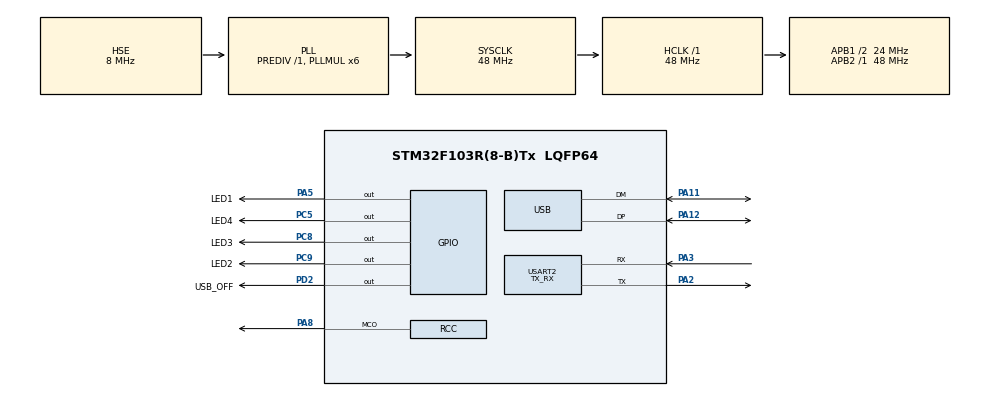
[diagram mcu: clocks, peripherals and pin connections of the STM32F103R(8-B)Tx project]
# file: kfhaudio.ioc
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Mcu.Family=STM32F1
Mcu.Name=STM32F103R(8-B)Tx
Mcu.Package=LQFP64
NVIC.PriorityGroup=NVIC_PRIORITYGROUP_4
NVIC.USB_LP_CAN1_RX0_IRQn=true\:0\:0\:false\:false\:true\:false\:true
PA11.Mode=Device
PA11.Signal=USB_DM
PA12.Mode=Device
PA12.Signal=USB_DP
PA13.Mode=Serial_Wire
PA13.Signal=SYS_JTMS-SWDIO
PA14.Mode=Serial_Wire
PA14.Signal=SYS_JTCK-SWCLK
PA2.Mode=Asynchronous
PA2.Signal=USART2_TX
PA3.Mode=Asynchronous
PA3.Signal=USART2_RX
PA5.GPIO_Label=LED1
PA5.Signal=GPIO_Output
PA8.GPIO_Speed=GPIO_SPEED_FREQ_HIGH
PA8.Mode=Clock-out
PA8.Signal=RCC_MCO
PC5.GPIO_Label=LED4
PC5.Signal=GPIO_Output
PC8.GPIO_Label=LED3
PC8.Signal=GPIO_Output
PC9.GPIO_Label=LED2
PC9.Signal=GPIO_Output
PD0-OSC_IN.Mode=HSE-External-Oscillator
PD0-OSC_IN.Signal=RCC_OSC_IN
PD1-OSC_OUT.Mode=HSE-External-Oscillator
PD1-OSC_OUT.Signal=RCC_OSC_OUT
PD2.GPIO_Label=USB_OFF
PD2.GPIO_PuPd=GPIO_PULLDOWN
PD2.Signal=GPIO_Output
ProjectManager.HeapSize=0x200
ProjectManager.StackSize=0x400
ProjectManager.TargetToolchain=SW4STM32
RCC.AHBFreq_Value=48000000
RCC.APB1CLKDivider=RCC_HCLK_DIV2
RCC.APB1Freq_Value=24000000
RCC.APB1TimFreq_Value=48000000
RCC.APB2Freq_Value=48000000
RCC.APB2TimFreq_Value=48000000
RCC.HCLKFreq_Value=48000000
RCC.PLLMUL=RCC_PLL_MUL6
RCC.RCC_MCOSource=RCC_MCO1SOURCE_PLLCLK
RCC.SYSCLKFreq_VALUE=48000000
RCC.SYSCLKSource=RCC_SYSCLKSOURCE_PLLCLK
RCC.USBFreq_Value=48000000
USART2.Mode=MODE_TX_RX
USART2.VirtualMode=VM_ASYNC
USB_DEVICE.CLASS_NAME_FS=CDC
USB_DEVICE.MANUFACTURER_STRING=SQ8KFH
USB_DEVICE.PRODUCT_STRING_CDC_FS=KFH Audio
USB_DEVICE.VirtualMode=Cdc
USB_DEVICE.VirtualModeFS=Cdc_FS
VP_USB_DEVICE_VS_USB_DEVICE_CDC_FS.Mode=CDC_FS
board=custom

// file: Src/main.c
/* USER CODE BEGIN Header */
/**
  ******************************************************************************
  * @file           : main.c
  * @brief          : Main program body
  ******************************************************************************
  * @attention
  *
  * <h2><center>&copy; Copyright (c) 2020 STMicroelectronics.
  * All rights reserved.</center></h2>
  *
  * This software component is licensed by ST under Ultimate Liberty license
  * SLA0044, the "License"; You may not use this file except in compliance with
  * the License. You may obtain a copy of the License at:
  *                             www.st.com/SLA0044
  *
  ******************************************************************************
  */
/* USER CODE END Header */
#include "main.h"
#include "usb_device.h"

UART_HandleTypeDef huart2;

void SystemClock_Config(void);
static void MX_GPIO_Init(void);
static void MX_USART2_UART_Init(void);

/* USER CODE BEGIN 0 */

int __io_putchar(int ch) {
	HAL_UART_Transmit(&huart2, (uint8_t*)&ch, 1, 1000);
	return ch;
}

/* USER CODE END 0 */

int main(void)
{

  /* MCU Configuration--------------------------------------------------------*/

  /* Reset of all peripherals, Initializes the Flash interface and the Systick. */
  HAL_Init();

  /* Configure the system clock */
  SystemClock_Config();

  /* Initialize all configured peripherals */
  MX_GPIO_Init();
  MX_USART2_UART_Init();
  MX_USB_DEVICE_Init();

  /* Infinite loop */
  /* USER CODE BEGIN WHILE */
  printf("Start\n");
  while (1)
  {
    /* USER CODE END WHILE */

  }
}

void SystemClock_Config(void)
{
  RCC_OscInitTypeDef RCC_OscInitStruct = {0};
  RCC_ClkInitTypeDef RCC_ClkInitStruct = {0};
  RCC_PeriphCLKInitTypeDef PeriphClkInit = {0};

  /** Initializes the RCC Oscillators according to the specified parameters
  * in the RCC_OscInitTypeDef structure.
  */
  RCC_OscInitStruct.OscillatorType = RCC_OSCILLATORTYPE_HSE;
  RCC_OscInitStruct.HSEState = RCC_HSE_ON;
  RCC_OscInitStruct.HSEPredivValue = RCC_HSE_PREDIV_DIV1;
  RCC_OscInitStruct.HSIState = RCC_HSI_ON;
  RCC_OscInitStruct.PLL.PLLState = RCC_PLL_ON;
  RCC_OscInitStruct.PLL.PLLSource = RCC_PLLSOURCE_HSE;
  RCC_OscInitStruct.PLL.PLLMUL = RCC_PLL_MUL6;
  if (HAL_RCC_OscConfig(&RCC_OscInitStruct) != HAL_OK)
  {
    Error_Handler();
  }
  /** Initializes the CPU, AHB and APB buses clocks
  */
  RCC_ClkInitStruct.ClockType = RCC_CLOCKTYPE_HCLK|RCC_CLOCKTYPE_SYSCLK
                              |RCC_CLOCKTYPE_PCLK1|RCC_CLOCKTYPE_PCLK2;
  RCC_ClkInitStruct.SYSCLKSource = RCC_SYSCLKSOURCE_PLLCLK;
  RCC_ClkInitStruct.AHBCLKDivider = RCC_SYSCLK_DIV1;
  RCC_ClkInitStruct.APB1CLKDivider = RCC_HCLK_DIV2;
  RCC_ClkInitStruct.APB2CLKDivider = RCC_HCLK_DIV1;

  if (HAL_RCC_ClockConfig(&RCC_ClkInitStruct, FLASH_LATENCY_1) != HAL_OK)
  {
    Error_Handler();
  }
  PeriphClkInit.PeriphClockSelection = RCC_PERIPHCLK_USB;
  PeriphClkInit.UsbClockSelection = RCC_USBCLKSOURCE_PLL;
  if (HAL_RCCEx_PeriphCLKConfig(&PeriphClkInit) != HAL_OK)
  {
    Error_Handler();
  }
  HAL_RCC_MCOConfig(RCC_MCO, RCC_MCO1SOURCE_PLLCLK, RCC_MCODIV_1);
}

static void MX_USART2_UART_Init(void)
{

  huart2.Instance = USART2;
  huart2.Init.BaudRate = 115200;
  huart2.Init.WordLength = UART_WORDLENGTH_8B;
  huart2.Init.StopBits = UART_STOPBITS_1;
  huart2.Init.Parity = UART_PARITY_NONE;
  huart2.Init.Mode = UART_MODE_TX_RX;
  huart2.Init.HwFlowCtl = UART_HWCONTROL_NONE;
  huart2.Init.OverSampling = UART_OVERSAMPLING_16;
  if (HAL_UART_Init(&huart2) != HAL_OK)
  {
    Error_Handler();
  }

}

static void MX_GPIO_Init(void)
{
  GPIO_InitTypeDef GPIO_InitStruct = {0};

  /* GPIO Ports Clock Enable */
  __HAL_RCC_GPIOD_CLK_ENABLE();
  __HAL_RCC_GPIOA_CLK_ENABLE();
  __HAL_RCC_GPIOC_CLK_ENABLE();

  /*Configure GPIO pin Output Level */
  HAL_GPIO_WritePin(LED1_GPIO_Port, LED1_Pin, GPIO_PIN_RESET);

  /*Configure GPIO pin Output Level */
  HAL_GPIO_WritePin(GPIOC, LED4_Pin|LED3_Pin|LED2_Pin, GPIO_PIN_RESET);

  /*Configure GPIO pin Output Level */
  HAL_GPIO_WritePin(USB_OFF_GPIO_Port, USB_OFF_Pin, GPIO_PIN_RESET);

  /*Configure GPIO pin : LED1_Pin */
  GPIO_InitStruct.Pin = LED1_Pin;
  GPIO_InitStruct.Mode = GPIO_MODE_OUTPUT_PP;
  GPIO_InitStruct.Pull = GPIO_NOPULL;
  GPIO_InitStruct.Speed = GPIO_SPEED_FREQ_LOW;
  HAL_GPIO_Init(LED1_GPIO_Port, &GPIO_InitStruct);

  /*Configure GPIO pins : LED4_Pin LED3_Pin LED2_Pin */
  GPIO_InitStruct.Pin = LED4_Pin|LED3_Pin|LED2_Pin;
  GPIO_InitStruct.Mode = GPIO_MODE_OUTPUT_PP;
  GPIO_InitStruct.Pull = GPIO_NOPULL;
  GPIO_InitStruct.Speed = GPIO_SPEED_FREQ_LOW;
  HAL_GPIO_Init(GPIOC, &GPIO_InitStruct);

  /*Configure GPIO pin : PA8 */
  GPIO_InitStruct.Pin = GPIO_PIN_8;
  GPIO_InitStruct.Mode = GPIO_MODE_AF_PP;
  GPIO_InitStruct.Speed = GPIO_SPEED_FREQ_HIGH;
  HAL_GPIO_Init(GPIOA, &GPIO_InitStruct);

  /*Configure GPIO pin : USB_OFF_Pin */
  GPIO_InitStruct.Pin = USB_OFF_Pin;
  GPIO_InitStruct.Mode = GPIO_MODE_OUTPUT_PP;
  GPIO_InitStruct.Pull = GPIO_PULLDOWN;
  GPIO_InitStruct.Speed = GPIO_SPEED_FREQ_LOW;
  HAL_GPIO_Init(USB_OFF_GPIO_Port, &GPIO_InitStruct);

}

void Error_Handler(void)
{
}

/************************ (C) COPYRIGHT STMicroelectronics *****END OF FILE****/
